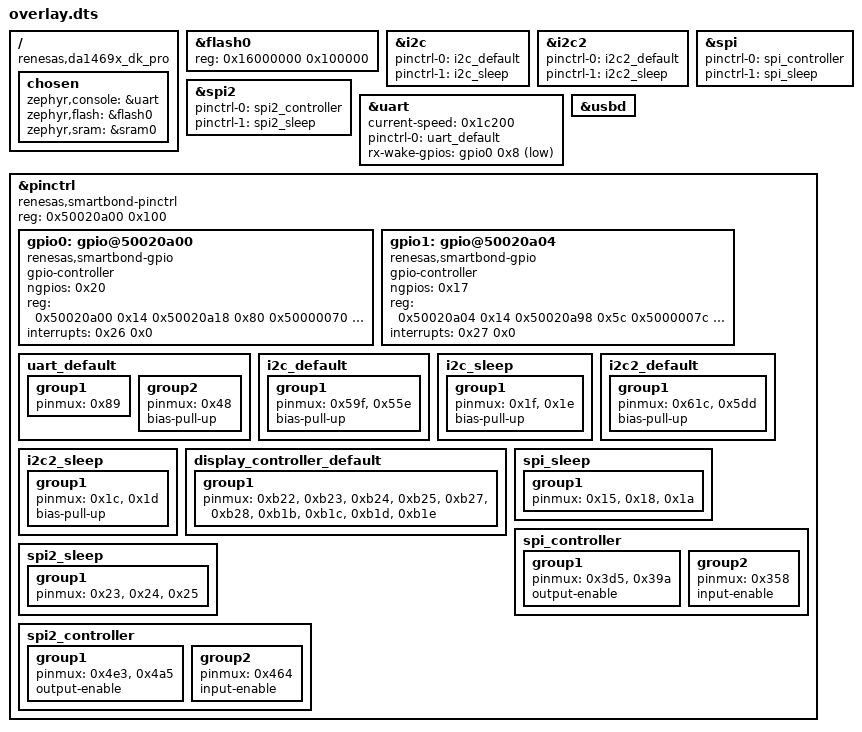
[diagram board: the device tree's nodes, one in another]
/ {
	compatible = "renesas,da1469x_dk_pro";
	chosen {
		zephyr,console = &uart;
		zephyr,flash = &flash0;
		zephyr,sram = &sram0;
	};
};
&flash0{
	reg = < 0x16000000 0x100000 >;
};
&gpio0{
	status = "okay";
};
&gpio1{
	status = "okay";
};
&i2c{
	pinctrl-0 = < &i2c_default >;
	pinctrl-1 = < &i2c_sleep >;
	pinctrl-names = "default", "sleep";
};
&i2c2{
	pinctrl-0 = < &i2c2_default >;
	pinctrl-1 = < &i2c2_sleep >;
	pinctrl-names = "default", "sleep";
};
&spi{
	pinctrl-0 = < &spi_controller >;
	pinctrl-1 = < &spi_sleep >;
	pinctrl-names = "default", "sleep";
};
&spi2{
	pinctrl-0 = < &spi2_controller >;
	pinctrl-1 = < &spi2_sleep >;
	pinctrl-names = "default", "sleep";
};
&uart{
	status = "okay";
	current-speed = < 0x1c200 >;
	pinctrl-0 = < &uart_default >;
	pinctrl-names = "default";
	rx-wake-gpios = < &gpio0 0x8 0x1 >;
};
&usbd{
	status = "okay";
};
&pinctrl{
	compatible = "renesas,smartbond-pinctrl";
	reg = < 0x50020a00 0x100 >;
	#address-cells = < 0x1 >;
	#size-cells = < 0x1 >;
	gpio0: gpio@50020a00 {
		compatible = "renesas,smartbond-gpio";
		gpio-controller;
		#gpio-cells = < 0x2 >;
		ngpios = < 0x20 >;
		reg = < 0x50020a00 0x14 0x50020a18 0x80 0x50000070 0xc 0x50000114 0x24 >;
		reg-names = "data", "mode", "latch", "wkup";
		interrupts = < 0x26 0x0 >;
		status = "okay";
	};
	gpio1: gpio@50020a04 {
		compatible = "renesas,smartbond-gpio";
		gpio-controller;
		#gpio-cells = < 0x2 >;
		ngpios = < 0x17 >;
		reg = < 0x50020a04 0x14 0x50020a98 0x5c 0x5000007c 0xc 0x50000118 0x24 >;
		reg-names = "data", "mode", "latch", "wkup";
		interrupts = < 0x27 0x0 >;
		status = "okay";
	};
	uart_default: uart_default {
		group1 {
			pinmux = < 0x89 >;
		};
		group2 {
			pinmux = < 0x48 >;
			bias-pull-up;
		};
	};
	i2c_default: i2c_default {
		group1 {
			pinmux = < 0x59f >, < 0x55e >;
			bias-pull-up;
		};
	};
	i2c_sleep: i2c_sleep {
		group1 {
			pinmux = < 0x1f >, < 0x1e >;
			bias-pull-up;
		};
	};
	i2c2_default: i2c2_default {
		group1 {
			pinmux = < 0x61c >, < 0x5dd >;
			bias-pull-up;
		};
	};
	i2c2_sleep: i2c2_sleep {
		group1 {
			pinmux = < 0x1c >, < 0x1d >;
			bias-pull-up;
		};
	};
	display_controller_default: display_controller_default {
		group1 {
			pinmux = < 0xb22 >, < 0xb23 >, < 0xb24 >, < 0xb25 >, < 0xb27 >, < 0xb28 >, < 0xb1b >, < 0xb1c >, < 0xb1d >, < 0xb1e >;
		};
	};
	spi_sleep: spi_sleep {
		group1 {
			pinmux = < 0x15 >, < 0x18 >, < 0x1a >;
		};
	};
	spi_controller: spi_controller {
		group1 {
			pinmux = < 0x3d5 >, < 0x39a >;
			output-enable;
		};
		group2 {
			pinmux = < 0x358 >;
			input-enable;
		};
	};
	spi2_sleep: spi2_sleep {
		group1 {
			pinmux = < 0x23 >, < 0x24 >, < 0x25 >;
		};
	};
	spi2_controller: spi2_controller {
		group1 {
			pinmux = < 0x4e3 >, < 0x4a5 >;
			output-enable;
		};
		group2 {
			pinmux = < 0x464 >;
			input-enable;
		};
	};
};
